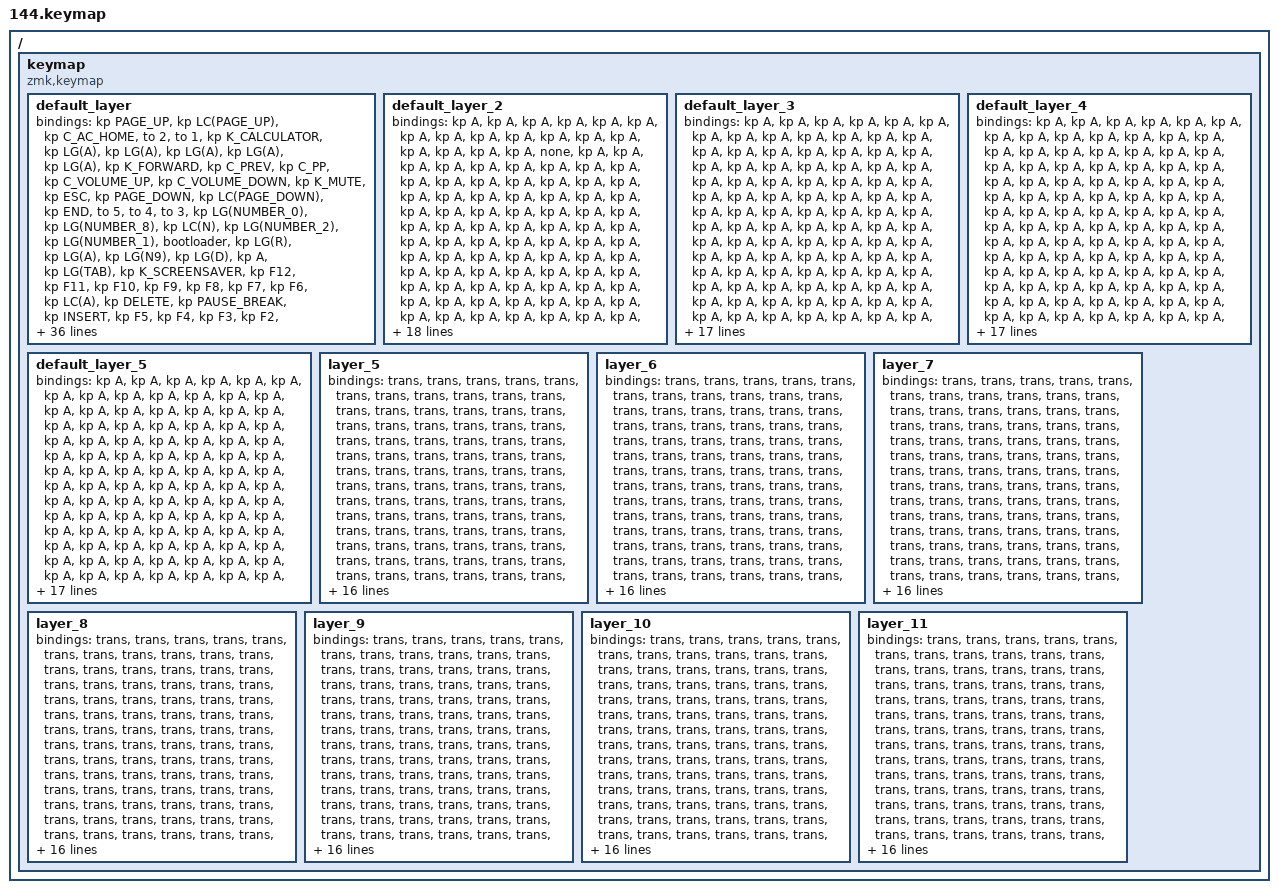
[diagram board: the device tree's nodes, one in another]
#include <behaviors.dtsi>
#include <dt-bindings/zmk/keys.h>

/ {
    keymap {
        compatible = "zmk,keymap";

        default_layer {
            // --------------------------------------------------------------------------------------------------------------------------------------------------------------------
            // |   ESC   |    Q    |    W    |    E    |    R    |    T    |                                          |    Y    |    U    |    I    |    O    |    P    |    \    |
            // |   TAB   |    A    |    S    |    D    |    F    |    G    |                                          |    H    |    J    |    K    |    L    |    ;    |    '    |
            // |  SHIFT  |    Z    |    X    |    C    |    V    |    B    | CTRL+A  | CTRL+C  |  |  CTRL+V |  CTRL+X |    N    |    M    |    ,    |    .    |    /    |  R CTRL |
            //                               |   GUI   |   DEL   | RETURN  |  SPACE  | ESCAPE  |  |  RETURN |  SPACE  |   TAB   |   BSPC  |  R ALT  |

            bindings = <
&kp PAGE_UP        &kp LC(PAGE_UP)    &kp C_AC_HOME     &to 2          &to 1          &kp K_CALCULATOR  &kp LG(A)         &kp LG(A)         &kp LG(A)        &kp LG(A)         &kp LG(A)         &kp K_FORWARD    &kp C_PREV    &kp C_PP         &kp C_VOLUME_UP  &kp C_VOLUME_DOWN  &kp K_MUTE    &kp ESC
&kp PAGE_DOWN      &kp LC(PAGE_DOWN)  &kp END           &to 5          &to 4          &to 3             &kp LG(NUMBER_0)  &kp LG(NUMBER_8)  &kp LC(N)        &kp LG(NUMBER_2)  &kp LG(NUMBER_1)  &bootloader      &kp LG(R)     &kp LG(A)        &kp LG(N9)       &kp LG(D)          &kp A         &kp LG(TAB)
&kp K_SCREENSAVER  &kp F12            &kp F11           &kp F10        &kp F9         &kp F8            &kp F7            &kp F6            &kp LC(A)        &kp DELETE        &kp PAUSE_BREAK   &kp INSERT       &kp F5        &kp F4           &kp F3           &kp F2             &kp F1        &kp K_MENU
&kp BACKSPACE      &kp EQUAL          &kp MINUS         &kp NUMBER_0   &kp NUMBER_9   &kp NUMBER_8      &kp NUMBER_7      &kp NUMBER_6      &kp KP_SLASH     &kp LS(LC(S))     &kp LC(LS(Y))     &kp KP_NUMLOCK   &kp NUMBER_5  &kp NUMBER_4     &kp NUMBER_3     &kp NUMBER_2       &kp NUMBER_1  &kp GRAVE
&kp BACKSLASH      &kp RIGHT_BRACKET  &kp LEFT_BRACKET  &kp P          &kp O          &kp I             &kp U             &kp Y             &kp KP_MULTIPLY  &kp KP_NUMBER_9   &kp KP_NUMBER_8   &kp KP_NUMBER_7  &kp T         &kp R            &kp E            &kp W              &kp Q         &kp TAB
&kp LG(E)          &kp A              &kp SINGLE_QUOTE  &kp SEMICOLON  &kp L          &kp K             &kp J             &kp H             &kp KP_MINUS     &kp KP_NUMBER_6   &kp KP_NUMBER_5   &kp KP_NUMBER_4  &kp G         &kp F            &kp D            &kp S              &kp A         &kp CAPSLOCK
&kp LG(Q)          &kp UP_ARROW       &kp SLASH         &kp DOT        &kp COMMA      &kp M             &kp N             &kp B             &kp KP_PLUS      &kp KP_NUMBER_3   &kp KP_NUMBER_2   &kp KP_NUMBER_1  &kp V         &kp C            &kp X            &kp Z              &none         &kp LEFT_SHIFT
&kp RIGHT_ARROW    &kp DOWN_ARROW     &kp LEFT_ARROW    &kp RCTRL      &kp RIGHT_ALT  &none             &kp SPACE         &none             &kp KP_ENTER     &kp KP_DOT        &kp KP_NUMBER_0   &kp KP_NUMBER_0  &kp SPACE     &kp LC(LS(TAB))  &kp LC(LA(TAB))  &kp LEFT_ALT       &kp LEFT_GUI  &kp LCTRL
&kp A              &kp A              &kp A             &kp A          &kp A          &kp A             &kp A             &kp A             &kp A            &kp A             &kp A             &kp A            &kp A         &kp A            &kp A
&kp R              &kp T              &kp N6            &kp N7         &kp N8         &kp N9            &kp N0            &kp N1            &kp N2           &kp N3            &kp N4            &kp N5                                                           &kp Q              &kp W         &kp E
            >;

            sensor-bindings = <&inc_dec_kp C_VOL_UP C_VOL_DN &inc_dec_kp PG_UP PG_DN &inc_dec_kp C_VOL_UP C_VOL_DN &inc_dec_kp PG_UP PG_DN &inc_dec_kp C_VOL_UP C_VOL_DN &inc_dec_kp PG_UP PG_DN>;
        };

        default_layer_2 {
            // --------------------------------------------------------------------------------------------------------------------------------------------------------------------
            // |   ESC   |    Q    |    W    |    E    |    R    |    T    |                                          |    Y    |    U    |    I    |    O    |    P    |    \    |
            // |   TAB   |    A    |    S    |    D    |    F    |    G    |                                          |    H    |    J    |    K    |    L    |    ;    |    '    |
            // |  SHIFT  |    Z    |    X    |    C    |    V    |    B    | CTRL+A  | CTRL+C  |  |  CTRL+V |  CTRL+X |    N    |    M    |    ,    |    .    |    /    |  R CTRL |
            //                               |   GUI   |   DEL   | RETURN  |  SPACE  | ESCAPE  |  |  RETURN |  SPACE  |   TAB   |   BSPC  |  R ALT  |

            bindings = <
&kp A  &kp A  &kp A  &kp A  &kp A  &kp A  &kp A  &kp A  &kp A  &kp A  &kp A  &kp A  &kp A  &kp A      &kp A      &kp A  &kp A  &none
&kp A  &kp A  &kp A  &kp A  &kp A  &kp A  &kp A  &kp A  &kp A  &kp A  &kp A  &kp A  &kp A  &kp A      &kp A      &kp A  &kp A  &kp A
&kp A  &kp A  &kp A  &kp A  &kp A  &kp A  &kp A  &kp A  &kp A  &kp A  &kp A  &kp A  &kp A  &kp A      &kp A      &kp A  &kp A  &kp A
&kp A  &kp A  &kp A  &kp A  &kp A  &kp A  &kp A  &kp A  &kp A  &kp A  &kp A  &kp A  &kp A  &kp A      &kp A      &kp A  &kp A  &kp A
&kp A  &kp A  &kp A  &kp A  &kp A  &kp A  &kp A  &kp A  &kp A  &kp A  &kp A  &kp A  &kp A  &kp A      &kp A      &kp A  &kp A  &kp A
&kp A  &kp A  &kp A  &kp A  &kp A  &kp A  &kp A  &kp A  &kp A  &kp A  &kp A  &kp A  &kp A  &kp A      &kp A      &kp A  &kp A  &kp A
&kp A  &kp A  &kp A  &kp A  &kp A  &kp A  &kp A  &kp A  &kp A  &kp A  &kp A  &kp A  &kp A  &kp A      &kp A      &kp A  &kp A  &kp A
&kp A  &kp A  &kp A  &kp A  &kp A  &kp A  &kp A  &kp A  &kp A  &kp A  &kp A  &kp A  &kp A  &kp LC(Y)  &kp LC(Z)  &kp A  &kp A  &kp A
&kp A  &kp A  &kp A  &kp A  &kp A  &kp A  &kp A  &kp A  &kp A  &kp A  &kp A  &kp A  &kp A  &kp A      &kp A
&kp A  &kp A  &kp A  &kp A  &kp A  &kp A  &kp A  &kp A  &kp A  &kp A  &kp A  &kp A                               &kp A  &kp A  &kp A
            >;

            sensor-bindings = <&inc_dec_kp C_VOL_UP C_VOL_DN &inc_dec_kp PG_UP PG_DN &inc_dec_kp C_VOL_UP C_VOL_DN &inc_dec_kp PG_UP PG_DN &inc_dec_kp C_VOL_UP C_VOL_DN &inc_dec_kp PG_UP PG_DN>;
        };

        default_layer_3 {
            // --------------------------------------------------------------------------------------------------------------------------------------------------------------------
            // |   ESC   |    Q    |    W    |    E    |    R    |    T    |                                          |    Y    |    U    |    I    |    O    |    P    |    \    |
            // |   TAB   |    A    |    S    |    D    |    F    |    G    |                                          |    H    |    J    |    K    |    L    |    ;    |    '    |
            // |  SHIFT  |    Z    |    X    |    C    |    V    |    B    | CTRL+A  | CTRL+C  |  |  CTRL+V |  CTRL+X |    N    |    M    |    ,    |    .    |    /    |  R CTRL |
            //                               |   GUI   |   DEL   | RETURN  |  SPACE  | ESCAPE  |  |  RETURN |  SPACE  |   TAB   |   BSPC  |  R ALT  |

            bindings = <
&kp A  &kp A  &kp A  &kp A  &kp A  &kp A  &kp A  &kp A  &kp A  &kp A  &kp A  &kp A  &kp A  &kp A  &kp A  &kp A  &kp A  &kp A
&kp A  &kp A  &kp A  &kp A  &kp A  &kp A  &kp A  &kp A  &kp A  &kp A  &kp A  &kp A  &kp A  &kp A  &kp A  &kp A  &kp A  &kp A
&kp A  &kp A  &kp A  &kp A  &kp A  &kp A  &kp A  &kp A  &kp A  &kp A  &kp A  &kp A  &kp A  &kp A  &kp A  &kp A  &kp A  &kp A
&kp A  &kp A  &kp A  &kp A  &kp A  &kp A  &kp A  &kp A  &kp A  &kp A  &kp A  &kp A  &kp A  &kp A  &kp A  &kp A  &kp A  &kp A
&kp A  &kp A  &kp A  &kp A  &kp A  &kp A  &kp A  &kp A  &kp A  &kp A  &kp A  &kp A  &kp A  &kp A  &kp A  &kp A  &kp A  &kp A
&kp A  &kp A  &kp A  &kp A  &kp A  &kp A  &kp A  &kp A  &kp A  &kp A  &kp A  &kp A  &kp A  &kp A  &kp A  &kp A  &kp A  &kp A
&kp A  &kp A  &kp A  &kp A  &kp A  &kp A  &kp A  &kp A  &kp A  &kp A  &kp A  &kp A  &kp A  &kp A  &kp A  &kp A  &kp A  &kp A
&kp A  &kp A  &kp A  &kp A  &kp A  &kp A  &kp A  &kp A  &kp A  &kp A  &kp A  &kp A  &kp A  &kp A  &kp A  &kp A  &kp A  &kp A
&kp A  &kp A  &kp A  &kp A  &kp A  &kp A  &kp A  &kp A  &kp A  &kp A  &kp A  &kp A  &kp A  &kp A  &kp A
&kp A  &kp A  &kp A  &kp A  &kp A  &kp A  &kp A  &kp A  &kp A  &kp A  &kp A  &kp A                       &kp A  &kp A  &kp A
            >;

            sensor-bindings = <&inc_dec_kp C_VOL_UP C_VOL_DN &inc_dec_kp PG_UP PG_DN &inc_dec_kp C_VOL_UP C_VOL_DN &inc_dec_kp PG_UP PG_DN &inc_dec_kp C_VOL_UP C_VOL_DN &inc_dec_kp PG_UP PG_DN>;
        };

        default_layer_4 {
            // --------------------------------------------------------------------------------------------------------------------------------------------------------------------
            // |   ESC   |    Q    |    W    |    E    |    R    |    T    |                                          |    Y    |    U    |    I    |    O    |    P    |    \    |
            // |   TAB   |    A    |    S    |    D    |    F    |    G    |                                          |    H    |    J    |    K    |    L    |    ;    |    '    |
            // |  SHIFT  |    Z    |    X    |    C    |    V    |    B    | CTRL+A  | CTRL+C  |  |  CTRL+V |  CTRL+X |    N    |    M    |    ,    |    .    |    /    |  R CTRL |
            //                               |   GUI   |   DEL   | RETURN  |  SPACE  | ESCAPE  |  |  RETURN |  SPACE  |   TAB   |   BSPC  |  R ALT  |

            bindings = <
&kp A  &kp A  &kp A  &kp A  &kp A  &kp A  &kp A  &kp A  &kp A  &kp A  &kp A  &kp A  &kp A  &kp A  &kp A  &kp A  &kp A  &kp A
&kp A  &kp A  &kp A  &kp A  &kp A  &kp A  &kp A  &kp A  &kp A  &kp A  &kp A  &kp A  &kp A  &kp A  &kp A  &kp A  &kp A  &kp A
&kp A  &kp A  &kp A  &kp A  &kp A  &kp A  &kp A  &kp A  &kp A  &kp A  &kp A  &kp A  &kp A  &kp A  &kp A  &kp A  &kp A  &kp A
&kp A  &kp A  &kp A  &kp A  &kp A  &kp A  &kp A  &kp A  &kp A  &kp A  &kp A  &kp A  &kp A  &kp A  &kp A  &kp A  &kp A  &kp A
&kp A  &kp A  &kp A  &kp A  &kp A  &kp A  &kp A  &kp A  &kp A  &kp A  &kp A  &kp A  &kp A  &kp A  &kp A  &kp A  &kp A  &kp A
&kp A  &kp A  &kp A  &kp A  &kp A  &kp A  &kp A  &kp A  &kp A  &kp A  &kp A  &kp A  &kp A  &kp A  &kp A  &kp A  &kp A  &kp A
&kp A  &kp A  &kp A  &kp A  &kp A  &kp A  &kp A  &kp A  &kp A  &kp A  &kp A  &kp A  &kp A  &kp A  &kp A  &kp A  &kp A  &kp A
&kp A  &kp A  &kp A  &kp A  &kp A  &kp A  &kp A  &kp A  &kp A  &kp A  &kp A  &kp A  &kp A  &kp A  &kp A  &kp A  &kp A  &kp A
&kp A  &kp A  &kp A  &kp A  &kp A  &kp A  &kp A  &kp A  &kp A  &kp A  &kp A  &kp A  &kp A  &kp A  &kp A
&kp A  &kp A  &kp A  &kp A  &kp A  &kp A  &kp A  &kp A  &kp A  &kp A  &kp A  &kp A                       &kp A  &kp A  &kp A
            >;

            sensor-bindings = <&inc_dec_kp C_VOL_UP C_VOL_DN &inc_dec_kp PG_UP PG_DN &inc_dec_kp C_VOL_UP C_VOL_DN &inc_dec_kp PG_UP PG_DN &inc_dec_kp C_VOL_UP C_VOL_DN &inc_dec_kp PG_UP PG_DN>;
        };

        default_layer_5 {
            // --------------------------------------------------------------------------------------------------------------------------------------------------------------------
            // |   ESC   |    Q    |    W    |    E    |    R    |    T    |                                          |    Y    |    U    |    I    |    O    |    P    |    \    |
            // |   TAB   |    A    |    S    |    D    |    F    |    G    |                                          |    H    |    J    |    K    |    L    |    ;    |    '    |
            // |  SHIFT  |    Z    |    X    |    C    |    V    |    B    | CTRL+A  | CTRL+C  |  |  CTRL+V |  CTRL+X |    N    |    M    |    ,    |    .    |    /    |  R CTRL |
            //                               |   GUI   |   DEL   | RETURN  |  SPACE  | ESCAPE  |  |  RETURN |  SPACE  |   TAB   |   BSPC  |  R ALT  |

            bindings = <
&kp A  &kp A  &kp A  &kp A  &kp A  &kp A  &kp A  &kp A  &kp A  &kp A  &kp A  &kp A  &kp A  &kp A  &kp A  &kp A  &kp A  &kp A
&kp A  &kp A  &kp A  &kp A  &kp A  &kp A  &kp A  &kp A  &kp A  &kp A  &kp A  &kp A  &kp A  &kp A  &kp A  &kp A  &kp A  &kp A
&kp A  &kp A  &kp A  &kp A  &kp A  &kp A  &kp A  &kp A  &kp A  &kp A  &kp A  &kp A  &kp A  &kp A  &kp A  &kp A  &kp A  &kp A
&kp A  &kp A  &kp A  &kp A  &kp A  &kp A  &kp A  &kp A  &kp A  &kp A  &kp A  &kp A  &kp A  &kp A  &kp A  &kp A  &kp A  &kp A
&kp A  &kp A  &kp A  &kp A  &kp A  &kp A  &kp A  &kp A  &kp A  &kp A  &kp A  &kp A  &kp A  &kp A  &kp A  &kp A  &kp A  &kp A
&kp A  &kp A  &kp A  &kp A  &kp A  &kp A  &kp A  &kp A  &kp A  &kp A  &kp A  &kp A  &kp A  &kp A  &kp A  &kp A  &kp A  &kp A
&kp A  &kp A  &kp A  &kp A  &kp A  &kp A  &kp A  &kp A  &kp A  &kp A  &kp A  &kp A  &kp A  &kp A  &kp A  &kp A  &kp A  &kp A
&kp A  &kp A  &kp A  &kp A  &kp A  &kp A  &kp A  &kp A  &kp A  &kp A  &kp A  &kp A  &kp A  &kp A  &kp A  &kp A  &kp A  &kp A
&kp A  &kp A  &kp A  &kp A  &kp A  &kp A  &kp A  &kp A  &kp A  &kp A  &kp A  &kp A  &kp A  &kp A  &kp A
&kp A  &kp A  &kp A  &kp A  &kp A  &kp A  &kp A  &kp A  &kp A  &kp A  &kp A  &kp A                       &kp A  &kp A  &kp A
            >;

            sensor-bindings = <&inc_dec_kp C_VOL_UP C_VOL_DN &inc_dec_kp PG_UP PG_DN &inc_dec_kp C_VOL_UP C_VOL_DN &inc_dec_kp PG_UP PG_DN &inc_dec_kp C_VOL_UP C_VOL_DN &inc_dec_kp PG_UP PG_DN>;
        };

        layer_5 {
            bindings = <
&trans  &trans  &trans  &trans  &trans  &trans  &trans  &trans  &trans  &trans  &trans  &trans  &trans  &trans  &trans  &trans  &trans  &trans
&trans  &trans  &trans  &trans  &trans  &trans  &trans  &trans  &trans  &trans  &trans  &trans  &trans  &trans  &trans  &trans  &trans  &trans
&trans  &trans  &trans  &trans  &trans  &trans  &trans  &trans  &trans  &trans  &trans  &trans  &trans  &trans  &trans  &trans  &trans  &trans
&trans  &trans  &trans  &trans  &trans  &trans  &trans  &trans  &trans  &trans  &trans  &trans  &trans  &trans  &trans  &trans  &trans  &trans
&trans  &trans  &trans  &trans  &trans  &trans  &trans  &trans  &trans  &trans  &trans  &trans  &trans  &trans  &trans  &trans  &trans  &trans
&trans  &trans  &trans  &trans  &trans  &trans  &trans  &trans  &trans  &trans  &trans  &trans  &trans  &trans  &trans  &trans  &trans  &trans
&trans  &trans  &trans  &trans  &trans  &trans  &trans  &trans  &trans  &trans  &trans  &trans  &trans  &trans  &trans  &trans  &trans  &trans
&trans  &trans  &trans  &trans  &trans  &trans  &trans  &trans  &trans  &trans  &trans  &trans  &trans  &trans  &trans  &trans  &trans  &trans
&trans  &trans  &trans  &trans  &trans  &trans  &trans  &trans  &trans  &trans  &trans  &trans  &trans  &trans  &trans
&trans  &trans  &trans  &trans  &trans  &trans  &trans  &trans  &trans  &trans  &trans  &trans                          &trans  &trans  &trans
            >;
        };

        layer_6 {
            bindings = <
&trans  &trans  &trans  &trans  &trans  &trans  &trans  &trans  &trans  &trans  &trans  &trans  &trans  &trans  &trans  &trans  &trans  &trans
&trans  &trans  &trans  &trans  &trans  &trans  &trans  &trans  &trans  &trans  &trans  &trans  &trans  &trans  &trans  &trans  &trans  &trans
&trans  &trans  &trans  &trans  &trans  &trans  &trans  &trans  &trans  &trans  &trans  &trans  &trans  &trans  &trans  &trans  &trans  &trans
&trans  &trans  &trans  &trans  &trans  &trans  &trans  &trans  &trans  &trans  &trans  &trans  &trans  &trans  &trans  &trans  &trans  &trans
&trans  &trans  &trans  &trans  &trans  &trans  &trans  &trans  &trans  &trans  &trans  &trans  &trans  &trans  &trans  &trans  &trans  &trans
&trans  &trans  &trans  &trans  &trans  &trans  &trans  &trans  &trans  &trans  &trans  &trans  &trans  &trans  &trans  &trans  &trans  &trans
&trans  &trans  &trans  &trans  &trans  &trans  &trans  &trans  &trans  &trans  &trans  &trans  &trans  &trans  &trans  &trans  &trans  &trans
&trans  &trans  &trans  &trans  &trans  &trans  &trans  &trans  &trans  &trans  &trans  &trans  &trans  &trans  &trans  &trans  &trans  &trans
&trans  &trans  &trans  &trans  &trans  &trans  &trans  &trans  &trans  &trans  &trans  &trans  &trans  &trans  &trans
&trans  &trans  &trans  &trans  &trans  &trans  &trans  &trans  &trans  &trans  &trans  &trans                          &trans  &trans  &trans
            >;
        };

        layer_7 {
            bindings = <
&trans  &trans  &trans  &trans  &trans  &trans  &trans  &trans  &trans  &trans  &trans  &trans  &trans  &trans  &trans  &trans  &trans  &trans
&trans  &trans  &trans  &trans  &trans  &trans  &trans  &trans  &trans  &trans  &trans  &trans  &trans  &trans  &trans  &trans  &trans  &trans
&trans  &trans  &trans  &trans  &trans  &trans  &trans  &trans  &trans  &trans  &trans  &trans  &trans  &trans  &trans  &trans  &trans  &trans
&trans  &trans  &trans  &trans  &trans  &trans  &trans  &trans  &trans  &trans  &trans  &trans  &trans  &trans  &trans  &trans  &trans  &trans
&trans  &trans  &trans  &trans  &trans  &trans  &trans  &trans  &trans  &trans  &trans  &trans  &trans  &trans  &trans  &trans  &trans  &trans
&trans  &trans  &trans  &trans  &trans  &trans  &trans  &trans  &trans  &trans  &trans  &trans  &trans  &trans  &trans  &trans  &trans  &trans
&trans  &trans  &trans  &trans  &trans  &trans  &trans  &trans  &trans  &trans  &trans  &trans  &trans  &trans  &trans  &trans  &trans  &trans
&trans  &trans  &trans  &trans  &trans  &trans  &trans  &trans  &trans  &trans  &trans  &trans  &trans  &trans  &trans  &trans  &trans  &trans
&trans  &trans  &trans  &trans  &trans  &trans  &trans  &trans  &trans  &trans  &trans  &trans  &trans  &trans  &trans
&trans  &trans  &trans  &trans  &trans  &trans  &trans  &trans  &trans  &trans  &trans  &trans                          &trans  &trans  &trans
            >;
        };

        layer_8 {
            bindings = <
&trans  &trans  &trans  &trans  &trans  &trans  &trans  &trans  &trans  &trans  &trans  &trans  &trans  &trans  &trans  &trans  &trans  &trans
&trans  &trans  &trans  &trans  &trans  &trans  &trans  &trans  &trans  &trans  &trans  &trans  &trans  &trans  &trans  &trans  &trans  &trans
&trans  &trans  &trans  &trans  &trans  &trans  &trans  &trans  &trans  &trans  &trans  &trans  &trans  &trans  &trans  &trans  &trans  &trans
&trans  &trans  &trans  &trans  &trans  &trans  &trans  &trans  &trans  &trans  &trans  &trans  &trans  &trans  &trans  &trans  &trans  &trans
&trans  &trans  &trans  &trans  &trans  &trans  &trans  &trans  &trans  &trans  &trans  &trans  &trans  &trans  &trans  &trans  &trans  &trans
&trans  &trans  &trans  &trans  &trans  &trans  &trans  &trans  &trans  &trans  &trans  &trans  &trans  &trans  &trans  &trans  &trans  &trans
&trans  &trans  &trans  &trans  &trans  &trans  &trans  &trans  &trans  &trans  &trans  &trans  &trans  &trans  &trans  &trans  &trans  &trans
&trans  &trans  &trans  &trans  &trans  &trans  &trans  &trans  &trans  &trans  &trans  &trans  &trans  &trans  &trans  &trans  &trans  &trans
&trans  &trans  &trans  &trans  &trans  &trans  &trans  &trans  &trans  &trans  &trans  &trans  &trans  &trans  &trans
&trans  &trans  &trans  &trans  &trans  &trans  &trans  &trans  &trans  &trans  &trans  &trans                          &trans  &trans  &trans
            >;
        };

        layer_9 {
            bindings = <
&trans  &trans  &trans  &trans  &trans  &trans  &trans  &trans  &trans  &trans  &trans  &trans  &trans  &trans  &trans  &trans  &trans  &trans
&trans  &trans  &trans  &trans  &trans  &trans  &trans  &trans  &trans  &trans  &trans  &trans  &trans  &trans  &trans  &trans  &trans  &trans
&trans  &trans  &trans  &trans  &trans  &trans  &trans  &trans  &trans  &trans  &trans  &trans  &trans  &trans  &trans  &trans  &trans  &trans
&trans  &trans  &trans  &trans  &trans  &trans  &trans  &trans  &trans  &trans  &trans  &trans  &trans  &trans  &trans  &trans  &trans  &trans
&trans  &trans  &trans  &trans  &trans  &trans  &trans  &trans  &trans  &trans  &trans  &trans  &trans  &trans  &trans  &trans  &trans  &trans
&trans  &trans  &trans  &trans  &trans  &trans  &trans  &trans  &trans  &trans  &trans  &trans  &trans  &trans  &trans  &trans  &trans  &trans
&trans  &trans  &trans  &trans  &trans  &trans  &trans  &trans  &trans  &trans  &trans  &trans  &trans  &trans  &trans  &trans  &trans  &trans
&trans  &trans  &trans  &trans  &trans  &trans  &trans  &trans  &trans  &trans  &trans  &trans  &trans  &trans  &trans  &trans  &trans  &trans
&trans  &trans  &trans  &trans  &trans  &trans  &trans  &trans  &trans  &trans  &trans  &trans  &trans  &trans  &trans
&trans  &trans  &trans  &trans  &trans  &trans  &trans  &trans  &trans  &trans  &trans  &trans                          &trans  &trans  &trans
            >;
        };

        layer_10 {
            bindings = <
&trans  &trans  &trans  &trans  &trans  &trans  &trans  &trans  &trans  &trans  &trans  &trans  &trans  &trans  &trans  &trans  &trans  &trans
&trans  &trans  &trans  &trans  &trans  &trans  &trans  &trans  &trans  &trans  &trans  &trans  &trans  &trans  &trans  &trans  &trans  &trans
&trans  &trans  &trans  &trans  &trans  &trans  &trans  &trans  &trans  &trans  &trans  &trans  &trans  &trans  &trans  &trans  &trans  &trans
&trans  &trans  &trans  &trans  &trans  &trans  &trans  &trans  &trans  &trans  &trans  &trans  &trans  &trans  &trans  &trans  &trans  &trans
&trans  &trans  &trans  &trans  &trans  &trans  &trans  &trans  &trans  &trans  &trans  &trans  &trans  &trans  &trans  &trans  &trans  &trans
&trans  &trans  &trans  &trans  &trans  &trans  &trans  &trans  &trans  &trans  &trans  &trans  &trans  &trans  &trans  &trans  &trans  &trans
&trans  &trans  &trans  &trans  &trans  &trans  &trans  &trans  &trans  &trans  &trans  &trans  &trans  &trans  &trans  &trans  &trans  &trans
&trans  &trans  &trans  &trans  &trans  &trans  &trans  &trans  &trans  &trans  &trans  &trans  &trans  &trans  &trans  &trans  &trans  &trans
&trans  &trans  &trans  &trans  &trans  &trans  &trans  &trans  &trans  &trans  &trans  &trans  &trans  &trans  &trans
&trans  &trans  &trans  &trans  &trans  &trans  &trans  &trans  &trans  &trans  &trans  &trans                          &trans  &trans  &trans
            >;
        };

        layer_11 {
            bindings = <
&trans  &trans  &trans  &trans  &trans  &trans  &trans  &trans  &trans  &trans  &trans  &trans  &trans  &trans  &trans  &trans  &trans  &trans
&trans  &trans  &trans  &trans  &trans  &trans  &trans  &trans  &trans  &trans  &trans  &trans  &trans  &trans  &trans  &trans  &trans  &trans
&trans  &trans  &trans  &trans  &trans  &trans  &trans  &trans  &trans  &trans  &trans  &trans  &trans  &trans  &trans  &trans  &trans  &trans
&trans  &trans  &trans  &trans  &trans  &trans  &trans  &trans  &trans  &trans  &trans  &trans  &trans  &trans  &trans  &trans  &trans  &trans
&trans  &trans  &trans  &trans  &trans  &trans  &trans  &trans  &trans  &trans  &trans  &trans  &trans  &trans  &trans  &trans  &trans  &trans
&trans  &trans  &trans  &trans  &trans  &trans  &trans  &trans  &trans  &trans  &trans  &trans  &trans  &trans  &trans  &trans  &trans  &trans
&trans  &trans  &trans  &trans  &trans  &trans  &trans  &trans  &trans  &trans  &trans  &trans  &trans  &trans  &trans  &trans  &trans  &trans
&trans  &trans  &trans  &trans  &trans  &trans  &trans  &trans  &trans  &trans  &trans  &trans  &trans  &trans  &trans  &trans  &trans  &trans
&trans  &trans  &trans  &trans  &trans  &trans  &trans  &trans  &trans  &trans  &trans  &trans  &trans  &trans  &trans
&trans  &trans  &trans  &trans  &trans  &trans  &trans  &trans  &trans  &trans  &trans  &trans                          &trans  &trans  &trans
            >;
        };
    };
};
